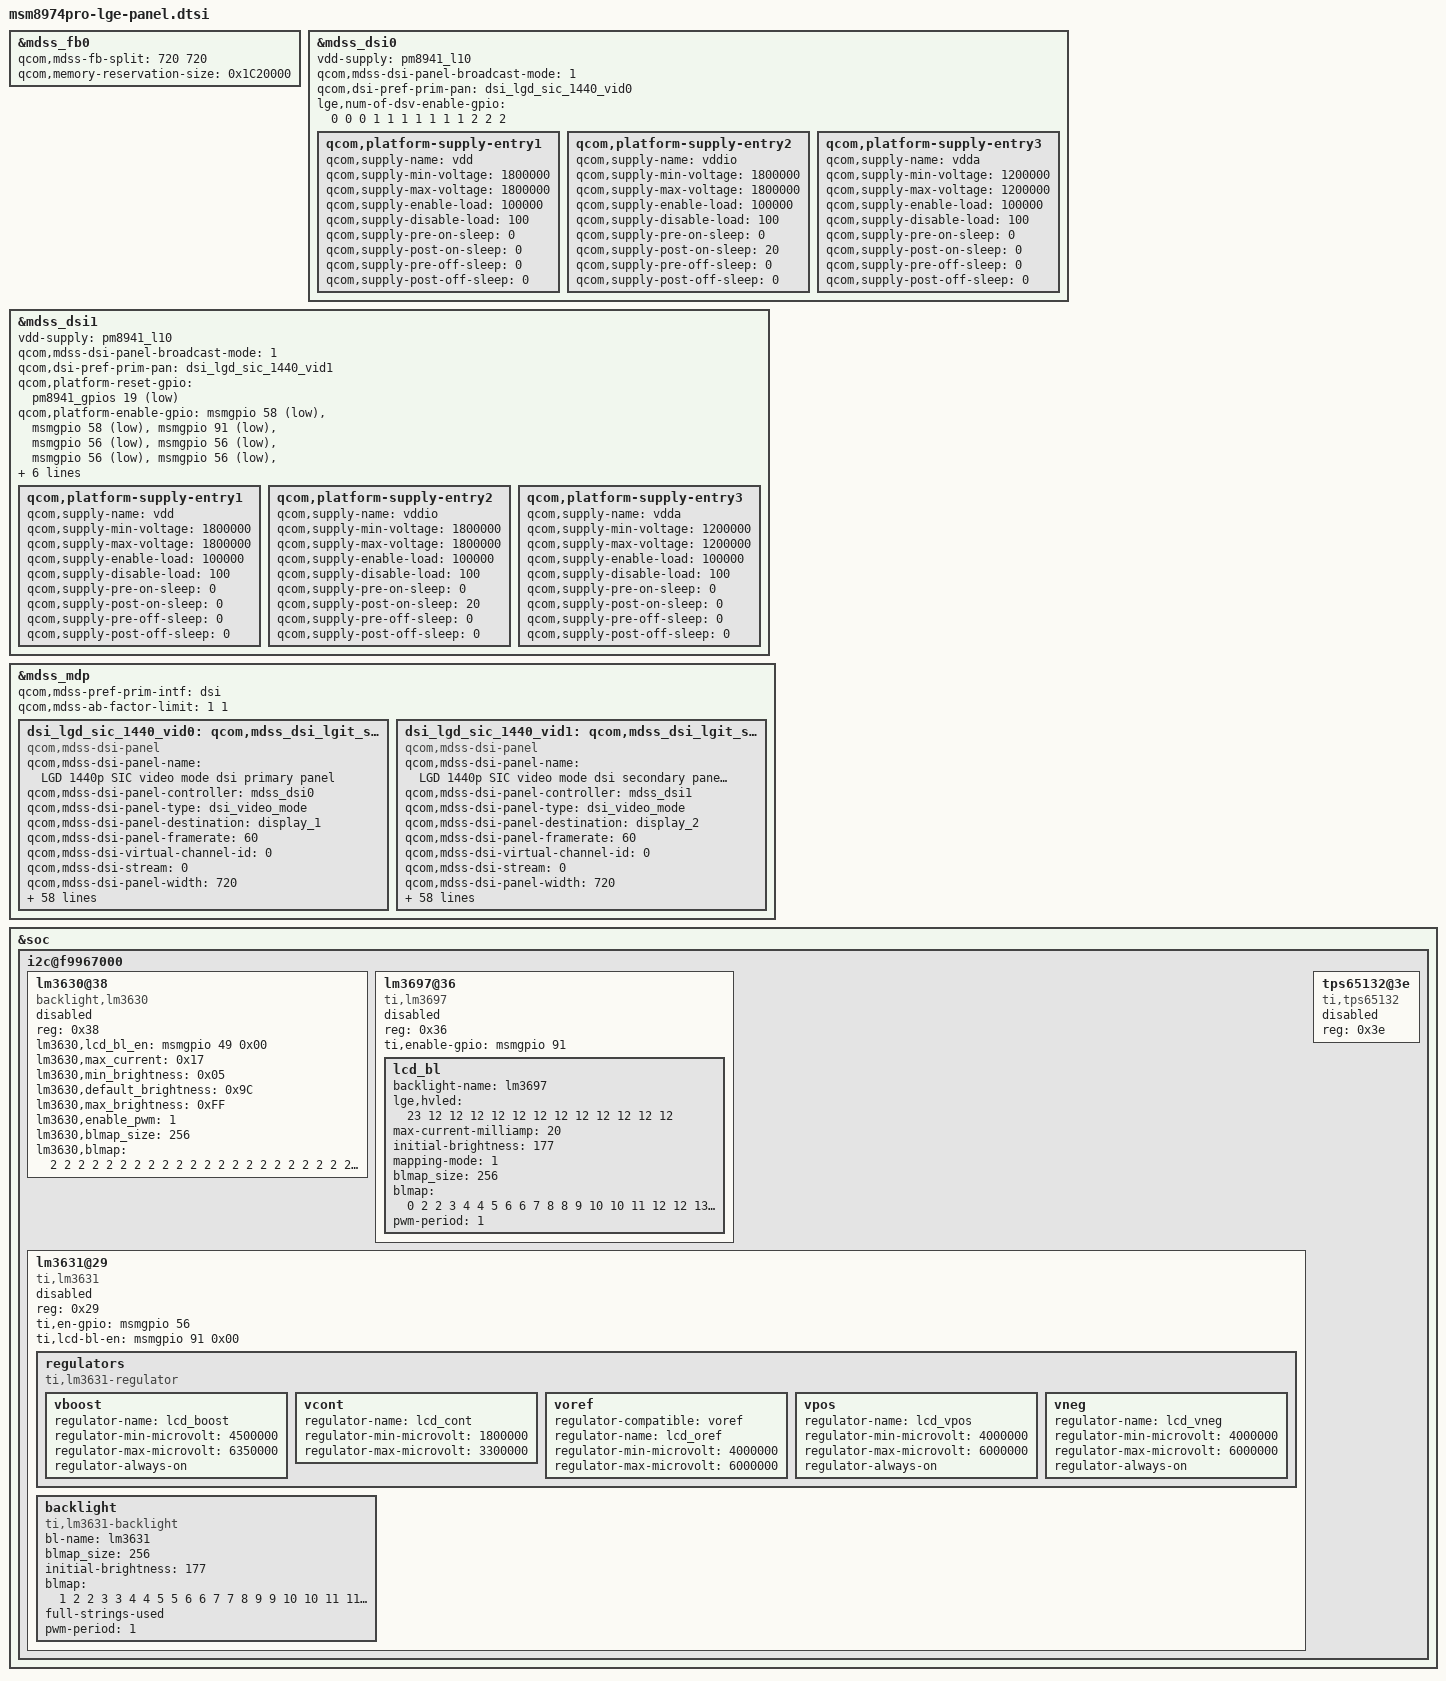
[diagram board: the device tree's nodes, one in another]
/* Copyright (c) 2012, Code Aurora Forum. All rights reserved.
 *
 * This program is free software; you can redistribute it and/or modify
 * it under the terms of the GNU General Public License version 2 and
 * only version 2 as published by the Free Software Foundation.
 *
 * This program is distributed in the hope that it will be useful,
 * but WITHOUT ANY WARRANTY; without even the implied warranty of
 * MERCHANTABILITY or FITNESS FOR A PARTICULAR PURPOSE.  See the
 * GNU General Public License for more details.
 */


/*---------------------------------------------------------------------------
 * This file is autogenerated file using gcdb parser. Please do not edit it.
 * Update input XML file to add a new entry or update variable in this file
 * VERSION = "1.0"
 *---------------------------------------------------------------------------*/

&mdss_fb0 {
	qcom,mdss-fb-split = <720 720>;
	qcom,memory-reservation-size = <0x1C20000>;
};

&mdss_dsi0 {
	vdd-supply = <&pm8941_l10>;
	qcom,mdss-dsi-panel-broadcast-mode = <1>;
	qcom,dsi-pref-prim-pan = <&dsi_lgd_sic_1440_vid0>;

	/delete-property/ qcom,platform-reset-gpio;
	/delete-property/ qcom,platform-enable-gpio;

	lge,num-of-dsv-enable-gpio = <
		0 0  // evb1  = 0 ; evb2  = 0
		0 1  // rev_a = 0 ; rev_b = 1
		1 1  // rev_c = 1 ; rev_d = 1
		1 1  // rev_e = 1 ; rev_f = 1
		1 1  // rev_g = 1 ; rev_h = 1
		2 2  // rev_10 = 1; rev_11 = 1
		2     // rev_12 = 1
		>;

	qcom,platform-supply-entry1 {
		qcom,supply-name = "vdd";
		qcom,supply-min-voltage = <1800000>;
		qcom,supply-max-voltage = <1800000>;
		qcom,supply-enable-load = <100000>;
		qcom,supply-disable-load = <100>;
		qcom,supply-pre-on-sleep = <0>;
		qcom,supply-post-on-sleep = <0>;
		qcom,supply-pre-off-sleep = <0>;
		qcom,supply-post-off-sleep = <0>;
	};

	qcom,platform-supply-entry2 {
		qcom,supply-name = "vddio";
		qcom,supply-min-voltage = <1800000>;
		qcom,supply-max-voltage = <1800000>;
		qcom,supply-enable-load = <100000>;
		qcom,supply-disable-load = <100>;
		qcom,supply-pre-on-sleep = <0>;
		qcom,supply-post-on-sleep = <20>;
		qcom,supply-pre-off-sleep = <0>;
		qcom,supply-post-off-sleep = <0>;
	};

	qcom,platform-supply-entry3 {
		qcom,supply-name = "vdda";
		qcom,supply-min-voltage = <1200000>;
		qcom,supply-max-voltage = <1200000>;
		qcom,supply-enable-load = <100000>;
		qcom,supply-disable-load = <100>;
		qcom,supply-pre-on-sleep = <0>;
		qcom,supply-post-on-sleep = <0>;
		qcom,supply-pre-off-sleep = <0>;
		qcom,supply-post-off-sleep = <0>;
	};
};

&mdss_dsi1 {
	vdd-supply = <&pm8941_l10>;

	qcom,mdss-dsi-panel-broadcast-mode = <1>;
	qcom,dsi-pref-prim-pan = <&dsi_lgd_sic_1440_vid1>;

	qcom,platform-reset-gpio = <&pm8941_gpios 19 1>;

	qcom,platform-enable-gpio = <&msmgpio 58 1>, // HW_REV_EVB1
		<&msmgpio 58 1>, // HW_REV_EVB2
		<&msmgpio 91 1>, // HW_REV_A
		<&msmgpio 56 1>, // HW_REV_B
		<&msmgpio 56 1>, // HW_REV_C
		<&msmgpio 56 1>, // HW_REV_D
		<&msmgpio 56 1>, // HW_REV_E
		<&msmgpio 56 1>, // HW_REV_F
		<&msmgpio 56 1>, // HW_REV_G
		<&msmgpio 56 1>, // HW_REV_H
		<&msmgpio 56 1>, // HW_REV_1.0
		<&msmgpio 56 1>, // HW_REV_1.1
		<&msmgpio 56 1>; // HW_REV_1.2

	lge,platform-enable-gpio2 = <&msmgpio 100 1>;

	lge,num-of-dsv-enable-gpio = <
		0 0  // evb1  = 0 ; evb2  = 0
		0 1  // rev_a = 0 ; rev_b = 1
		1 1  // rev_c = 1 ; rev_d = 1
		1 1  // rev_e = 1 ; rev_f = 1
		1 1  // rev_g = 1 ; rev_h = 1
		2 2  // rev_10 = 1; rev_11 = 1
		2     // rev_12 = 1
		>;

	qcom,platform-supply-entry1 {
		qcom,supply-name = "vdd";
		qcom,supply-min-voltage = <1800000>;
		qcom,supply-max-voltage = <1800000>;
		qcom,supply-enable-load = <100000>;
		qcom,supply-disable-load = <100>;
		qcom,supply-pre-on-sleep = <0>;
		qcom,supply-post-on-sleep = <0>;
		qcom,supply-pre-off-sleep = <0>;
		qcom,supply-post-off-sleep = <0>;
	};

	qcom,platform-supply-entry2 {
		qcom,supply-name = "vddio";
		qcom,supply-min-voltage = <1800000>;
		qcom,supply-max-voltage = <1800000>;
		qcom,supply-enable-load = <100000>;
		qcom,supply-disable-load = <100>;
		qcom,supply-pre-on-sleep = <0>;
		qcom,supply-post-on-sleep = <20>;
		qcom,supply-pre-off-sleep = <0>;
		qcom,supply-post-off-sleep = <0>;
	};

	qcom,platform-supply-entry3 {
		qcom,supply-name = "vdda";
		qcom,supply-min-voltage = <1200000>;
		qcom,supply-max-voltage = <1200000>;
		qcom,supply-enable-load = <100000>;
		qcom,supply-disable-load = <100>;
		qcom,supply-pre-on-sleep = <0>;
		qcom,supply-post-on-sleep = <0>;
		qcom,supply-pre-off-sleep = <0>;
		qcom,supply-post-off-sleep = <0>;
	};
};

&mdss_mdp {

	/delete-property/ qcom,mdss-ad-off;
	qcom,mdss-pref-prim-intf = "dsi";
	qcom,mdss-ab-factor-limit = <1 1>;	/*  cam tuning times  */

	dsi_lgd_sic_1440_vid0: qcom,mdss_dsi_lgit_sic_mipi0_video {
		compatible = "qcom,mdss-dsi-panel";
		qcom,mdss-dsi-panel-name = "LGD 1440p SIC video mode dsi primary panel ";
		qcom,mdss-dsi-panel-controller = <&mdss_dsi0>;
		qcom,mdss-dsi-panel-type = "dsi_video_mode";
		qcom,mdss-dsi-panel-destination = "display_1";
		qcom,mdss-dsi-panel-framerate = <60>;
		qcom,mdss-dsi-virtual-channel-id = <0>;
		qcom,mdss-dsi-stream = <0>;
		qcom,mdss-dsi-panel-width = <720>;
		qcom,mdss-dsi-panel-height = <2560>;
		qcom,mdss-dsi-h-front-porch = <12>;
		qcom,mdss-dsi-h-back-porch = <40>;
		qcom,mdss-dsi-h-pulse-width = <12>;
		qcom,mdss-dsi-h-sync-skew = <0>;
		qcom,mdss-dsi-v-back-porch = <5>;
		qcom,mdss-dsi-v-front-porch = <5>;
		qcom,mdss-dsi-v-pulse-width = <1>;
		qcom,mdss-dsi-h-left-border = <0>;
		qcom,mdss-dsi-h-right-border = <0>;
		qcom,mdss-dsi-v-top-border = <0>;
		qcom,mdss-dsi-v-bottom-border = <0>;
		qcom,mdss-dsi-bpp = <24>;
		qcom,mdss-dsi-color-order = "rgb_swap_rgb";
		qcom,mdss-dsi-underflow-color = <0xff>;
		qcom,mdss-dsi-border-color = <0>;
		qcom,mdss-dsi-on-command = [
			05 01 00 00 05 00 01 01
			15 01 00 00 00 00 02 B0 AC
			39 01 00 00 00 00 06 B1 47 F0 80 00 00
			39 01 00 00 00 00 04 B2 77 28 27
			39 01 00 00 00 00 07 B3 0F 12 22 20 00 A0
			39 01 00 00 00 00 08 B4 13 10 10 0A 0A 0A 0A
			39 01 00 00 00 00 0A B5 30 26 1A 1A 10 10 40 10 05
			39 01 00 00 00 00 04 B7 62 01 3F
			39 01 00 00 00 00 03 C0 03 00
			39 01 00 00 00 00 06 C1 22 80 F0 01 CF
			15 01 00 00 00 00 02 C2 22
			39 01 00 00 00 00 07 C3 06 88 0C 00 1B 1B
			39 01 00 00 00 00 04 C4 47 0C 0C
			39 01 00 00 00 00 07 C5 41 81 05 05 59 02
			39 01 00 00 00 00 03 CA 20 B9
			39 01 00 00 00 00 02 C9 3F
			39 01 00 00 00 00 0C D0 03 30 35 55 22 34 0F 06 51 33 02
			39 01 00 00 00 00 0C D1 03 30 35 55 22 34 0F 06 51 33 02
			39 01 00 00 00 00 0C D2 03 30 35 55 22 34 0F 06 51 33 02
			39 01 00 00 00 00 0C D3 03 30 35 55 22 34 0F 06 51 33 02
			39 01 00 00 00 00 0C D4 03 30 35 55 22 34 0F 06 51 33 02
			39 01 00 00 00 00 0C D5 03 30 35 55 22 34 0F 06 51 33 02
			39 01 00 00 00 00 05 E9 00 00 00 00
			39 01 00 00 00 00 03 B6 00 00
			15 01 00 00 00 00 02 51 FF
			15 01 00 00 00 00 02 5E 00
			15 01 00 00 00 00 02 53 2C
			39 01 00 00 00 00 07 B8 11 11 11 38 00 00
			15 01 00 00 00 00 02 55 81
			15 01 00 00 00 00 02 F0 33
			39 01 00 00 00 00 05 F1 00 00 02 02
			39 01 00 00 00 00 04 F2 01 00 40
			39 01 00 00 00 00 06 F3 00 00 00 00 00
			39 01 00 00 00 00 02 F4 00
			39 01 00 00 00 00 04 F5 01 00 61
			39 01 00 00 00 00 04 F6 03 00 61
			39 01 00 00 00 00 04 F7 00 00 00
			39 01 00 00 00 00 11 F8 40 40 40 40 40 40 40 40 00 00 00 00 00 00 00 00
			39 01 00 00 00 00 11 F9 40 40 40 40 40 40 40 40 00 00 00 00 00 00 00 00
			39 01 00 00 00 00 11 FA 40 40 40 40 40 40 40 40 00 00 00 00 00 00 00 00
			05 01 00 00 05 00 01 11
			05 01 00 00 00 00 01 29
			];
		qcom,mdss-dsi-off-command = [05 01 00 00 14 00 01 28
			05 01 00 00 50 00 01 10];
		qcom,mdss-dsi-on-command-state = "dsi_lp_mode";
		qcom,mdss-dsi-off-command-state = "dsi_hs_mode";
		qcom,mdss-dsi-h-sync-pulse = <0>;
		qcom,mdss-dsi-traffic-mode = "non_burst_sync_event";
		qcom,mdss-dsi-lane-map = "lane_map_0123";
		qcom,mdss-dsi-lane-hs = <1>;
		qcom,mdss-dsi-bllp-eof-power-mode;
		qcom,mdss-dsi-bllp-power-mode;
		qcom,mdss-dsi-lane-0-state;
		qcom,mdss-dsi-lane-1-state;
		qcom,mdss-dsi-lane-2-state;
		qcom,mdss-dsi-lane-3-state;
		qcom,mdss-dsi-panel-broadcast-mode = <1>;
		qcom,mdss-dsi-panel-timings = [C5 2C 1E 00 5A 5E
			22 30 25 03 04 00];
		qcom,mdss-dsi-t-clk-post = <0x03>;
		qcom,mdss-dsi-t-clk-pre = <0x25>;
		qcom,mdss-dsi-bl-min-level = <1>;
		qcom,mdss-dsi-bl-max-level = <1511>;
		qcom,mdss-dsi-dma-trigger = "trigger_sw";
		qcom,mdss-dsi-mdp-trigger = "none";
		qcom,mdss-dsi-bl-pmic-control-type = "bl_others";
		qcom,mdss-dsi-pan-enable-dynamic-fps;
		qcom,mdss-dsi-pan-fps-update = "dfps_immediate_porch_mode";
		qcom,mdss-dsi-reset-sequence = <1 5>;
		qcom,mdss-dsi-lp11-init;
		qcom,cont-splash-enabled;
		qcom,mdss-dsi-tx-eot-append;
		qcom,mdss-pan-physical-width-dimension = <68>;
		qcom,mdss-pan-physical-height-dimension = <120>;

		// ief
		qcom,panel-ief-on-cmds = [
			15 01 00 00 00 00 02 B0 AC
			15 01 00 00 00 00 02 55 81
			15 01 00 00 00 00 02 F0 7F
			39 01 00 00 00 00 05 F1 00 00 01 01
			39 01 00 00 00 00 04 F2 04 00 80
			39 01 00 00 00 00 06 F3 00 00 00 00 00
			39 01 00 00 00 00 03 F4 00 14
			39 01 00 00 00 00 04 F5 07 00 03
			39 01 00 00 00 00 04 F6 00 00 00
			39 01 00 00 00 00 04 F7 00 00 00
			39 01 00 00 00 00 11 F8 40 40 40 40 40 40 40 40 00 00 00 00 00 00 00 00
			39 01 00 00 00 00 11 F9 40 40 40 40 40 40 40 40 00 00 00 00 00 00 00 00
			39 01 00 00 00 00 11 FA 40 40 40 40 40 40 40 40 00 00 00 00 00 00 00 00
			];
		qcom,panel-ief-off-cmds = [
			15 01 00 00 00 00 02 B0 AC
			15 01 00 00 00 00 02 55 81
			15 01 00 00 00 00 02 F0 26
			39 01 00 00 00 00 05 F1 00 00 00 00
			39 01 00 00 00 00 04 F2 01 00 40
			39 01 00 00 00 00 06 F3 00 00 00 00 00
			39 01 00 00 00 00 02 F4 05
			39 01 00 00 00 00 04 F5 02 00 83
			39 01 00 00 00 00 04 F6 00 00 00
			39 01 00 00 00 00 04 F7 00 00 00
			39 01 00 00 00 00 11 F8 40 40 40 40 40 40 40 40 00 00 00 00 00 00 00 00
			39 01 00 00 00 00 11 F9 40 40 40 40 40 40 40 40 00 00 00 00 00 00 00 00
			39 01 00 00 00 00 11 FA 40 40 40 40 40 40 40 40 00 00 00 00 00 00 00 00
			];
		qcom,ief-on-dsi-state = "dsi_hs_mode";
		qcom,ief-off-dsi-state = "dsi_hs_mode";
	};

	dsi_lgd_sic_1440_vid1: qcom,mdss_dsi_lgit_sic_mipi1_video {
		compatible = "qcom,mdss-dsi-panel";
		qcom,mdss-dsi-panel-name = "LGD 1440p SIC video mode dsi secondary panel ";
		qcom,mdss-dsi-panel-controller = <&mdss_dsi1>;
		qcom,mdss-dsi-panel-type = "dsi_video_mode";
		qcom,mdss-dsi-panel-destination = "display_2";
		qcom,mdss-dsi-panel-framerate = <60>;
		qcom,mdss-dsi-virtual-channel-id = <0>;
		qcom,mdss-dsi-stream = <0>;
		qcom,mdss-dsi-panel-width = <720>;
		qcom,mdss-dsi-panel-height = <2560>;
		qcom,mdss-dsi-h-front-porch = <12>;
		qcom,mdss-dsi-h-back-porch = <40>;
		qcom,mdss-dsi-h-pulse-width = <12>;
		qcom,mdss-dsi-h-sync-skew = <0>;
		qcom,mdss-dsi-v-back-porch = <5>;
		qcom,mdss-dsi-v-front-porch = <5>;
		qcom,mdss-dsi-v-pulse-width = <1>;
		qcom,mdss-dsi-h-left-border = <0>;
		qcom,mdss-dsi-h-right-border = <0>;
		qcom,mdss-dsi-v-top-border = <0>;
		qcom,mdss-dsi-v-bottom-border = <0>;
		qcom,mdss-dsi-bpp = <24>;
		qcom,mdss-dsi-color-order = "rgb_swap_rgb";
		qcom,mdss-dsi-underflow-color = <0xff>;
		qcom,mdss-dsi-border-color = <0>;
		qcom,mdss-dsi-on-command = [
			05 01 00 00 05 00 01 01
			15 01 00 00 00 00 02 B0 AC
			39 01 00 00 00 00 06 B1 47 F0 80 00 00
			39 01 00 00 00 00 04 B2 77 28 27
			39 01 00 00 00 00 07 B3 0F 12 22 20 00 A0
			39 01 00 00 00 00 08 B4 13 10 10 0A 0A 0A 0A
			39 01 00 00 00 00 0A B5 30 26 1A 1A 10 10 40 10 05
			39 01 00 00 00 00 04 B7 62 01 3F
			39 01 00 00 00 00 03 C0 03 00
			39 01 00 00 00 00 06 C1 22 80 F0 01 CF
			15 01 00 00 00 00 02 C2 22
			39 01 00 00 00 00 07 C3 06 88 0C 00 1B 1B
			39 01 00 00 00 00 04 C4 47 0C 0C
			39 01 00 00 00 00 07 C5 41 81 05 05 59 02
			39 01 00 00 00 00 03 CA 20 B9
			39 01 00 00 00 00 02 C9 3F
			39 01 00 00 00 00 0C D0 03 30 35 55 22 34 0F 06 51 33 02
			39 01 00 00 00 00 0C D1 03 30 35 55 22 34 0F 06 51 33 02
			39 01 00 00 00 00 0C D2 03 30 35 55 22 34 0F 06 51 33 02
			39 01 00 00 00 00 0C D3 03 30 35 55 22 34 0F 06 51 33 02
			39 01 00 00 00 00 0C D4 03 30 35 55 22 34 0F 06 51 33 02
			39 01 00 00 00 00 0C D5 03 30 35 55 22 34 0F 06 51 33 02
			39 01 00 00 00 00 05 E9 00 00 00 00
			39 01 00 00 00 00 03 B6 00 00
			15 01 00 00 00 00 02 51 FF
			15 01 00 00 00 00 02 5E 00
			15 01 00 00 00 00 02 53 2C
			39 01 00 00 00 00 07 B8 11 11 11 38 00 00
			15 01 00 00 00 00 02 55 81
			15 01 00 00 00 00 02 F0 33
			39 01 00 00 00 00 05 F1 00 00 02 02
			39 01 00 00 00 00 04 F2 01 00 40
			39 01 00 00 00 00 06 F3 00 00 00 00 00
			39 01 00 00 00 00 02 F4 00
			39 01 00 00 00 00 04 F5 01 00 61
			39 01 00 00 00 00 04 F6 03 00 61
			39 01 00 00 00 00 04 F7 00 00 00
			39 01 00 00 00 00 11 F8 40 40 40 40 40 40 40 40 00 00 00 00 00 00 00 00
			39 01 00 00 00 00 11 F9 40 40 40 40 40 40 40 40 00 00 00 00 00 00 00 00
			39 01 00 00 00 00 11 FA 40 40 40 40 40 40 40 40 00 00 00 00 00 00 00 00
			05 01 00 00 05 00 01 11
			05 01 00 00 00 00 01 29
			];
		qcom,mdss-dsi-off-command = [05 01 00 00 14 00 01 28
			05 01 00 00 50 00 01 10];
		qcom,mdss-dsi-on-command-state = "dsi_lp_mode";
		qcom,mdss-dsi-off-command-state = "dsi_hs_mode";
		qcom,mdss-dsi-h-sync-pulse = <0>;
		qcom,mdss-dsi-traffic-mode = "non_burst_sync_event";
		qcom,mdss-dsi-lane-map = "lane_map_0123";
		qcom,mdss-dsi-lane-hs = <1>;
		qcom,mdss-dsi-bllp-eof-power-mode;
		qcom,mdss-dsi-bllp-power-mode;
		qcom,mdss-dsi-lane-0-state;
		qcom,mdss-dsi-lane-1-state;
		qcom,mdss-dsi-lane-2-state;
		qcom,mdss-dsi-lane-3-state;
		qcom,mdss-dsi-panel-broadcast-mode = <1>;
		qcom,mdss-dsi-panel-timings = [C5 2C 1E 00 5A 5E
			22 30 25 03 04 00];
		qcom,mdss-dsi-t-clk-post = <0x03>;
		qcom,mdss-dsi-t-clk-pre = <0x25>;
		qcom,mdss-dsi-bl-min-level = <1>;
		qcom,mdss-dsi-bl-max-level = <1511>;
		qcom,mdss-dsi-dma-trigger = "trigger_sw";
		qcom,mdss-dsi-mdp-trigger = "none";
		qcom,mdss-dsi-bl-pmic-control-type = "bl_others";
		qcom,mdss-dsi-pan-enable-dynamic-fps;
		qcom,mdss-dsi-pan-fps-update = "dfps_immediate_porch_mode";
		qcom,mdss-dsi-reset-sequence = <1 5>;
		qcom,mdss-dsi-lp11-init;
		qcom,cont-splash-enabled;
		qcom,mdss-dsi-tx-eot-append;
		qcom,mdss-pan-physical-width-dimension = <68>;
		qcom,mdss-pan-physical-height-dimension = <120>;

		// ief
		qcom,panel-ief-on-cmds = [
			15 01 00 00 00 00 02 B0 AC
			15 01 00 00 00 00 02 55 81
			15 01 00 00 00 00 02 F0 7F
			39 01 00 00 00 00 05 F1 00 00 01 01
			39 01 00 00 00 00 04 F2 04 00 80
			39 01 00 00 00 00 06 F3 00 00 00 00 00
			39 01 00 00 00 00 03 F4 00 14
			39 01 00 00 00 00 04 F5 07 00 03
			39 01 00 00 00 00 04 F6 00 00 00
			39 01 00 00 00 00 04 F7 00 00 00
			39 01 00 00 00 00 11 F8 40 40 40 40 40 40 40 40 00 00 00 00 00 00 00 00
			39 01 00 00 00 00 11 F9 40 40 40 40 40 40 40 40 00 00 00 00 00 00 00 00
			39 01 00 00 00 00 11 FA 40 40 40 40 40 40 40 40 00 00 00 00 00 00 00 00
			];
		qcom,panel-ief-off-cmds = [
			15 01 00 00 00 00 02 B0 AC
			15 01 00 00 00 00 02 55 81
			15 01 00 00 00 00 02 F0 26
			39 01 00 00 00 00 05 F1 00 00 00 00
			39 01 00 00 00 00 04 F2 01 00 40
			39 01 00 00 00 00 06 F3 00 00 00 00 00
			39 01 00 00 00 00 02 F4 05
			39 01 00 00 00 00 04 F5 02 00 83
			39 01 00 00 00 00 04 F6 00 00 00
			39 01 00 00 00 00 04 F7 00 00 00
			39 01 00 00 00 00 11 F8 40 40 40 40 40 40 40 40 00 00 00 00 00 00 00 00
			39 01 00 00 00 00 11 F9 40 40 40 40 40 40 40 40 00 00 00 00 00 00 00 00
			39 01 00 00 00 00 11 FA 40 40 40 40 40 40 40 40 00 00 00 00 00 00 00 00
			];
		qcom,ief-on-dsi-state = "dsi_hs_mode";
		qcom,ief-off-dsi-state = "dsi_hs_mode";
	};
};

&soc {
	i2c@f9967000 {
		lm3630@38 {
			compatible = "backlight,lm3630";
			status = "disable";
			reg = <0x38>;
			lm3630,lcd_bl_en = <&msmgpio 49 0x00>;
			lm3630,max_current = <0x17>;
			lm3630,min_brightness = <0x05>;
			lm3630,default_brightness = <0x9C>;
			lm3630,max_brightness = <0xFF>;
			lm3630,enable_pwm = <1>;
			lm3630,blmap_size = <256>;
			lm3630,blmap = <
				2 2 2 2 2 2 2 2 2 2 2 2 2 2 2
				2 2 2 2 2 2 2 2 2 2 2 2 2 2 2
				2 2 2 2 2 2 2 2 3 3 3 3 3 3 3
				3 3 3 3 3 3 3 3 4 4 4 4 4 4 4
				4 4 4 5 5 5 5 5 5 5 6 6 6 6 6
				6 7 7 7 7 7 8 8 8 8 9 9 9 9 10
				10 10 10 11 11 11 12 12 12 13 13 13 14 14 14
				15 15 15 16 16 17 17 17 18 18 19 19 20 20 21
				21 22 22 23 23 24 24 25 25 26 27 27 28 28 29
				30 30 31 32 32 33 34 34 35 36 36 37 38 39 39
				40 41 42 43 43 44 45 46 47 48 49 50 51 51 52
				53 54 55 56 57 58 59 60 61 63 64 65 66 67 68
				69 70 72 73 74 75 76 78 79 80 82 83 84 85 87
				88 90 91 92 94 95 97 98 100 101 103 104 106 107 109
				110 112 114 115 117 119 120 122 124 126 127 129 131 133 134
				136 138 140 142 144 146 148 150 152 154 156 158 160 162 164
				166 168 170 173 175 177 179 181 184 186 188 191 193 195 198
				200>;
		};

		lm3697@36 {
			compatible = "ti,lm3697";
			status = "disable";
			reg = <0x36>;

			/* GPIO134 for HWEN pin */
			ti,enable-gpio = <&msmgpio 91 0x00>;

			lcd_bl {
				backlight-name = "lm3697";
				lge,hvled = <
					23 12  // evb1  = hvled2, hvled3  ; evb2  = hvled1, hvled2
					12 12  // rev_a = hvled1, hvled2 ; rev_b = hvled1, hvled2
					12 12  // rev_c = hvled1, hvled2 ; rev_d = hvled1, hvled2
					12 12  // rev_e = hvled1, hvled2 ; rev_f = hvled1, hvled2
					12 12  // rev_g = hvled1, hvled2 ; rev_h = hvled1, hvled2
					12 12  // rev_10 = hvled1, hvled2 ; rev_11 = hvled1, hvled2
					12     // rev_12 = hvled1, hvled2
					>;
				max-current-milliamp = <20>;
				initial-brightness = <177>;
				/* mapping-mode, 0:exp, 1:linear */
				mapping-mode = <1>;

				blmap_size = <256>;
				blmap = <
					0 2 2 3 4 4 5 6 6 7 8 8 9 10 10 11 12 12 13 14 14 15 16 16
					17 18 18 19 19 20 21 21 22 23 23 24 25 25 26 27 27 28 29 29
					30 31 31 32 33 33 34 34 34 35 35 35 35 35 35 36 36 36 36 37
					38 39 40 40 41 42 43 44 45 47 48 50 51 53 54 56 57 59 60 62
					64 67 69 71 73 75 78 80 82 85 89 92 96 99 102 106 109 113
					116 120 123 127 131 134 138 141 145 149 152 156 161 167 172
					178 183 189 194 200 205 210 215 220 225 230 235 239 244 249
					254 259 264 271 277 284 291 297 304 311 317 324 332 340 348
					356 364 371 379 387 395 403 411 420 429 438 447 457 466 475
					484 493 502 511 520 529 538 547 555 564 573 582 591 600 612
					625 637 650 662 675 687 700 712 725 737 750 762 775 788 800
					813 825 838 851 863 876 888 901 913 926 938 951 963 976 990
					1004 1018 1032 1046 1060 1074 1088 1116 1124 1130 1146 1163
					1179 1196 1212 1228 1245 1261 1278 1294 1312 1331 1349 1368
					1386 1404 1423 1441 1460 1478 1498 1518 1539 1559 1579 1599
					1619 1640 1660 1680 1704 1727 1751 1774 1798 1821 1845 1868
					1892
					>;

				pwm-period = <1>;
			};
		};

		lm3631@29 {
			compatible = "ti,lm3631";
			status = "disable";
			reg = <0x29>;
			ti,en-gpio = <&msmgpio 56 0x00>;
			ti,lcd-bl-en = <&msmgpio 91 0x00>;

			regulators {
				compatible = "ti,lm3631-regulator";

				vboost {
					regulator-name = "lcd_boost";
					regulator-min-microvolt = <4500000>;
					regulator-max-microvolt = <6350000>;
					regulator-always-on;
				};

				vcont {
					regulator-name = "lcd_cont";
					regulator-min-microvolt = <1800000>;
					regulator-max-microvolt = <3300000>;
				};

				voref {
					regulator-compatible = "voref";
					regulator-name = "lcd_oref";
					regulator-min-microvolt = <4000000>;
					regulator-max-microvolt = <6000000>;
				};

				vpos {
					regulator-name = "lcd_vpos";
					regulator-min-microvolt = <4000000>;
					regulator-max-microvolt = <6000000>;
					regulator-always-on;
				};

				vneg {
					regulator-name = "lcd_vneg";
					regulator-min-microvolt = <4000000>;
					regulator-max-microvolt = <6000000>;
					regulator-always-on;
				};
			};

			backlight {
				compatible = "ti,lm3631-backlight";
				bl-name = "lm3631";
				blmap_size = <256>;
				initial-brightness = <177>;
				blmap = <
					1 2 2 3 3 4 4 5 5 6 6 7 7 8 9 9 10 10 11 11 12 12 13 13
					14 15 15 16 16 17 17 18 18 19 19 20 20 21 22 22 23 23 24 24
					25 25 26 26 27 27 28 28 29 29 29 29 30 30 30 30 31 31 31 32
					32 33 33 34 34 35 35 36 37 39 40 41 42 44 45 46	47 49 50 52
					54 55 57 59 61 63 64 66 68 71 73 76 79 82 84 87 90 92 95 98
					100 103 106 109 111 114 117 120	122 125 129 134 138 142 147
					151 155 160 164 168 172 176 180 184 188 192 196 200 204 208
					212 218 224 230 236 242 248 254 260 266 272 278 283 289 295
					301 307 313 318 324 330 337 344 351 358 365 372 379 386 393
					400 407 415 422 430 437 445 452 460 467 475 482 492 502 512
					522 532 542 552 562 572 582 592 602 612 622 632 642 652 662
					672 682 692 702 712 722 731 741 751 761 771 781 792 803 813
					824 835 846 857 868 878 889 900 914 928 941 955 969 983 997
					1010 1024 1038 1052 1066 1081 1095 1109 1123 1137 1152 1166
					1180 1196 1212 1228 1244 1260 1276 1292 1308 1324 1340 1359
					1378 1397 1416 1435 1454 1473 1492 1511>;
				full-strings-used;

				pwm-period = <1>;
			};
		};

		tps65132@3e {
			compatible = "ti,tps65132";
			status = "disable";
			reg = <0x3e>;
		};

	};

};
